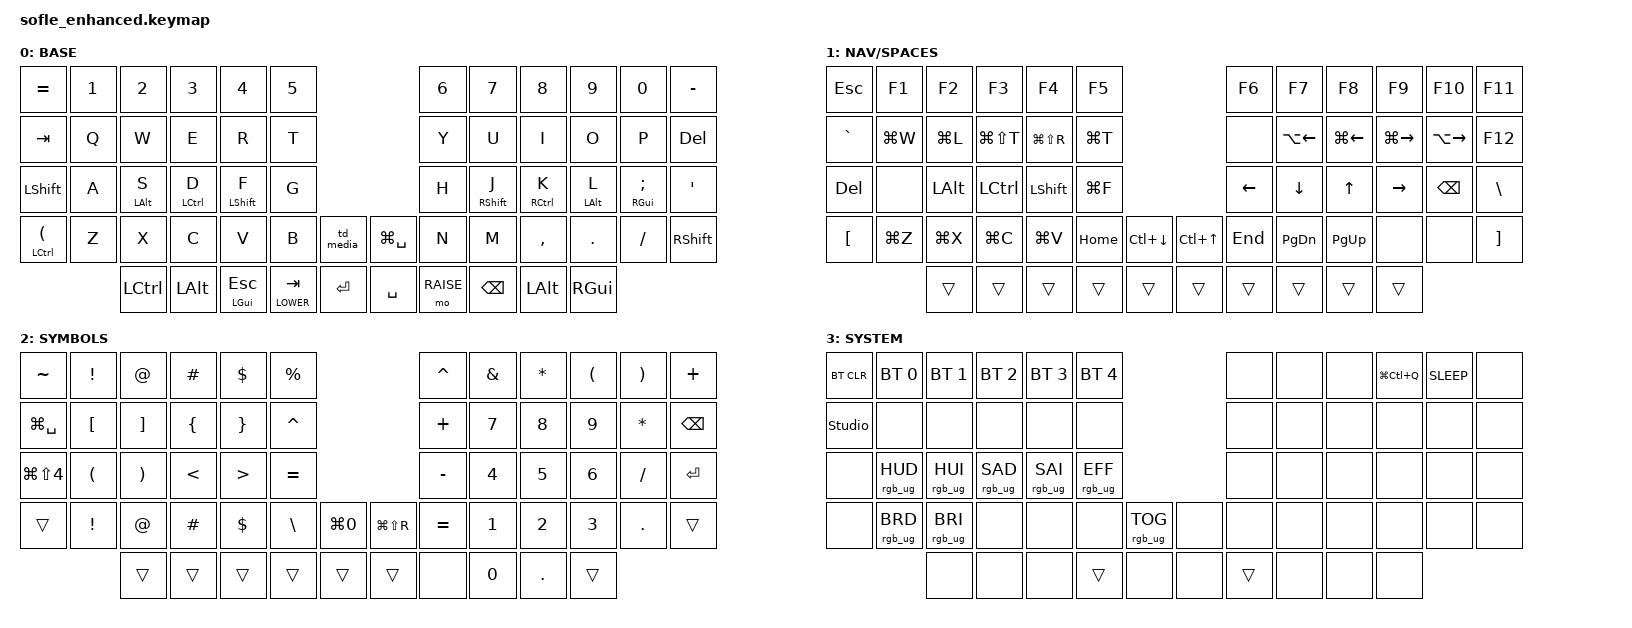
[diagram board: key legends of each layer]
/*
 * Copyright (c) 2020 The ZMK Contributors
 *
 * SPDX-License-Identifier: MIT
 *
 * Enhanced Clamshell Developer Keymap for Sofle RGB v2.1
 * Optimized for Ghostty + Zellij + Neovim + Vimium on macOS
 */

#include <behaviors.dtsi>
#include <dt-bindings/zmk/keys.h>
#include <dt-bindings/zmk/bt.h>
#include <dt-bindings/zmk/rgb.h>
#include <dt-bindings/zmk/ext_power.h>
#include <dt-bindings/zmk/outputs.h>

#define BASE 0
#define LOWER 1
#define RAISE 2
#define ADJUST 3

/ {
    // Activate ADJUST layer by pressing raise and lower together
    conditional_layers {
        compatible = "zmk,conditional-layers";
        adjust_layer {
            if-layers = <LOWER RAISE>;
            then-layer = <ADJUST>;
        };
    };

    behaviors {
        // Balanced Home Row Modifiers
        hm: homerow_mods {
            compatible = "zmk,behavior-hold-tap";
            label = "HOMEROW_MODS";
            #binding-cells = <2>;
            tapping-term-ms = <200>;
            quick-tap-ms = <175>;
            require-prior-idle-ms = <150>;
            flavor = "balanced";
            bindings = <&kp>, <&kp>;
        };

        // Left Knob Click Tap-Dance: 1 Tap = Play/Pause | 2 Taps = Next Track | Hold = Mute
        td_media: tap_dance_media {
            compatible = "zmk,behavior-tap-dance";
            #binding-cells = <0>;
            tapping-term-ms = <220>;
            bindings = <&kp C_PP>, <&kp C_NEXT>, <&kp C_MUTE>;
        };
    };

    keymap {
        compatible = "zmk,keymap";

        // =========================================================================
        // LAYER 0: BASE (Typing & Frictionless Scrobbling)
        // =========================================================================
        default_layer {
            display-name = "BASE";
            bindings = <
&kp EQUAL       &kp N1  &kp N2   &kp N3      &kp N4      &kp N5                                         &kp N6  &kp N7       &kp N8      &kp N9      &kp N0        &kp MINUS
&kp TAB         &kp Q   &kp W    &kp E       &kp R       &kp T                                          &kp Y   &kp U        &kp I       &kp O       &kp P         &kp DEL
&kp LSHFT       &kp A   &hm LALT S &hm LCTRL D &hm LSHFT F &kp G                                        &kp H   &hm RSHFT J  &hm RCTRL K &hm LALT L  &hm RGUI SEMI &kp SQT
&hm LCTRL LPAR  &kp Z   &kp X    &kp C       &kp V       &kp B       &td_media       &kp LG(SPACE)      &kp N   &kp M        &kp COMMA   &kp DOT     &kp FSLH      &kp RSHFT
                        &kp LCTRL &kp LALT   &mt LGUI ESC &lt LOWER TAB &kp RET      &kp SPACE &mo RAISE &kp BSPC &kp LALT    &kp RGUI
            >;

            // Left: Volume Up/Down | Right: Continuous Line-by-Line Scrobble (Up/Down)
            sensor-bindings = <&inc_dec_kp C_VOL_UP C_VOL_DN &inc_dec_kp UP DOWN>;
        };

        // =========================================================================
        // LAYER 1: LOWER (Navigation, Word Scrubbing & macOS Spaces)
        // Activate by holding Left Thumb (lt LOWER TAB) -> Right Hand turns encoder
        // =========================================================================
        lower_layer {
            display-name = "NAV/SPACES";
            bindings = <
&kp ESC         &kp F1        &kp F2        &kp F3           &kp F4          &kp F5                                    &kp F6       &kp F7       &kp F8       &kp F9        &kp F10      &kp F11
&kp GRAVE       &kp LG(W)     &kp LG(L)     &kp LG(LS(T))    &kp LG(LS(R))   &kp LG(T)                                 &none        &kp LA(LEFT) &kp LG(LEFT) &kp LG(RIGHT) &kp LA(RIGHT)&kp F12
&kp DEL         &none         &kp LALT      &kp LCTRL        &kp LSHFT       &kp LG(F)                                 &kp LEFT     &kp DOWN     &kp UP       &kp RIGHT     &kp BSPC     &kp BSLH
&kp LBKT        &kp LG(Z)     &kp LG(X)     &kp LG(C)        &kp LG(V)       &kp HOME      &kp LC(DOWN)  &kp LC(UP)    &kp END      &kp PG_DN    &kp PG_UP    &none         &none        &kp RBKT
                              &trans        &trans           &trans          &trans        &trans        &trans &trans &trans       &trans       &trans
            >;

            // Left: Volume | Right: 3-Finger Desktop Spaces Swipe (Ctrl + Right/Left)
            sensor-bindings = <&inc_dec_kp C_VOL_UP C_VOL_DN &inc_dec_kp LC(RIGHT) LC(LEFT)>;
        };

        // =========================================================================
        // LAYER 2: RAISE (Programming Symbols, Numpad & Zoom)
        // Activate by holding Right Thumb (mo RAISE) -> Left Hand turns encoder
        // =========================================================================
        raise_layer {
            display-name = "SYMBOLS";
            bindings = <
&kp TILDE       &kp EXCL      &kp AT        &kp HASH         &kp DLLR        &kp PRCNT                                 &kp CARET    &kp AMPS     &kp ASTRK    &kp LPAR      &kp RPAR     &kp PLUS
&kp LG(SPACE)   &kp LBKT      &kp RBKT      &kp LBRC         &kp RBRC        &kp CARET                                 &kp PLUS     &kp N7       &kp N8       &kp N9        &kp ASTRK    &kp BSPC
&kp LG(LS(N4))  &kp LPAR      &kp RPAR      &kp LT           &kp GT          &kp EQUAL                                 &kp MINUS    &kp N4       &kp N5       &kp N6        &kp FSLH     &kp RET
&trans          &kp EXCL      &kp AT        &kp HASH         &kp DLLR        &kp BSLH      &kp LG(N0)    &kp LG(LS(R)) &kp EQUAL    &kp N1       &kp N2       &kp N3        &kp DOT      &trans
                              &trans        &trans           &trans          &trans        &trans        &trans &none  &kp N0       &kp DOT      &trans
            >;

            // Left: Pinch-to-Zoom In/Out (Cmd + / Cmd -) | Right: Fast Page Scrub (PgUp/PgDn)
            sensor-bindings = <&inc_dec_kp LG(PLUS) LG(MINUS) &inc_dec_kp PG_UP PG_DN>;
        };

        // =========================================================================
        // LAYER 3: ADJUST (System, Bluetooth, Lighting & Terminal Split Mastery)
        // Activate by holding LOWER + RAISE together
        // =========================================================================
        adjust_layer {
            display-name = "SYSTEM";
            bindings = <
&bt BT_CLR        &bt BT_SEL 0    &bt BT_SEL 1    &bt BT_SEL 2    &bt BT_SEL 3    &bt BT_SEL 4                            &none &none &none &kp LG(LC(Q)) &kp C_SLEEP &none
&studio_unlock    &none           &none           &none           &none           &none                                   &none &none &none &none         &none       &none
&none             &rgb_ug RGB_HUD &rgb_ug RGB_HUI &rgb_ug RGB_SAD &rgb_ug RGB_SAI &rgb_ug RGB_EFF                         &none &none &none &none         &none       &none
&none             &rgb_ug RGB_BRD &rgb_ug RGB_BRI &none           &none           &none            &rgb_ug RGB_TOG &none  &none &none &none &none         &none       &none
                                  &none           &none           &none           &trans           &none           &none  &trans &none &none &none
            >;

            // Left: Ghostty Split Navigation (Cmd+Alt+Left/Right) | Right: Neovim Jump List (Ctrl+O/I)
            sensor-bindings = <&inc_dec_kp LA(LG(RIGHT)) LA(LG(LEFT)) &inc_dec_kp LC(O) LC(I)>;
        };
    };
};
